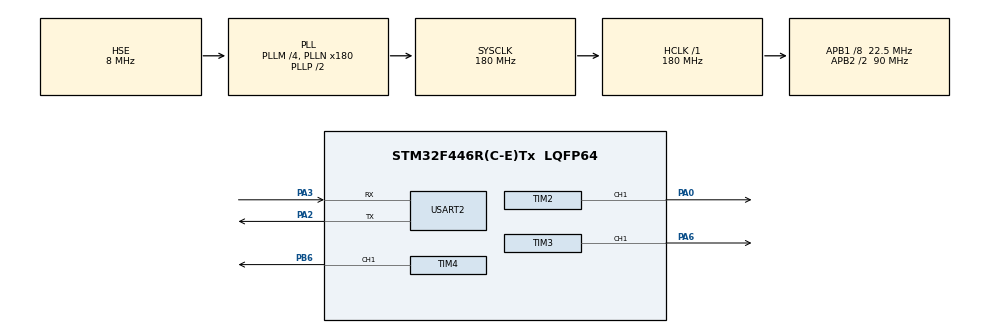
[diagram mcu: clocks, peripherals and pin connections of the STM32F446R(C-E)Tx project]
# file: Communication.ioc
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Mcu.Family=STM32F4
Mcu.Name=STM32F446R(C-E)Tx
Mcu.Package=LQFP64
NVIC.PriorityGroup=NVIC_PRIORITYGROUP_0
NVIC.TIM2_IRQn=true\:0\:0\:false\:false\:true\:true\:true
NVIC.TIM3_IRQn=true\:0\:0\:false\:false\:true\:true\:true
NVIC.TIM4_IRQn=true\:0\:0\:false\:false\:true\:true\:true
NVIC.USART2_IRQn=true\:0\:0\:false\:false\:true\:true\:true
PA0-WKUP.Signal=S_TIM2_CH1_ETR
PA2.Mode=Asynchronous
PA2.Signal=USART2_TX
PA3.Mode=Asynchronous
PA3.Signal=USART2_RX
PA6.Signal=S_TIM3_CH1
PB6.Signal=S_TIM4_CH1
PH0-OSC_IN.Mode=HSE-External-Oscillator
PH0-OSC_IN.Signal=RCC_OSC_IN
PH1-OSC_OUT.Mode=HSE-External-Oscillator
PH1-OSC_OUT.Signal=RCC_OSC_OUT
ProjectManager.HeapSize=0x200
ProjectManager.StackSize=0x400
ProjectManager.TargetToolchain=STM32CubeIDE
RCC.48MHZClocksFreq_Value=84000000
RCC.AHBFreq_Value=180000000
RCC.APB1CLKDivider=RCC_HCLK_DIV8
RCC.APB1Freq_Value=22500000
RCC.APB1TimFreq_Value=45000000
RCC.APB2CLKDivider=RCC_HCLK_DIV2
RCC.APB2Freq_Value=90000000
RCC.APB2TimFreq_Value=180000000
RCC.CortexFreq_Value=180000000
RCC.FLatency-AdvancedSettings=FLASH_LATENCY_5
RCC.HCLKFreq_Value=180000000
RCC.HSE_VALUE=8000000
RCC.HSI_VALUE=16000000
RCC.PLLM=4
RCC.PLLN=180
RCC.PLLSourceVirtual=RCC_PLLSOURCE_HSE
RCC.SYSCLKFreq_VALUE=180000000
RCC.SYSCLKSource=RCC_SYSCLKSOURCE_PLLCLK
RCC.USBFreq_Value=180000000
RCC.VCOOutputFreq_Value=360000000
SH.S_TIM2_CH1_ETR.0=TIM2_CH1,PWM Generation1 CH1
SH.S_TIM3_CH1.0=TIM3_CH1,PWM Generation1 CH1
SH.S_TIM4_CH1.0=TIM4_CH1,PWM Generation1 CH1
TIM2.Channel-PWM\ Generation1\ CH1=TIM_CHANNEL_1
TIM2.Period=1000-1
TIM2.Prescaler=900-1
TIM3.Channel-PWM\ Generation1\ CH1=TIM_CHANNEL_1
TIM3.Period=1000-1
TIM3.Prescaler=900-1
TIM4.Channel-PWM\ Generation1\ CH1=TIM_CHANNEL_1
TIM4.Period=1000-1
TIM4.Prescaler=900-1
USART2.VirtualMode=VM_ASYNC
VP_TIM2_VS_ClockSourceINT.Mode=Internal
VP_TIM3_VS_ClockSourceINT.Mode=Internal
VP_TIM4_VS_ClockSourceINT.Mode=Internal
board=NUCLEO-F446RE

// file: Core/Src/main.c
/* USER CODE BEGIN Header */
/**
  ******************************************************************************
  * @file           : main.c
  * @brief          : Main program body
  ******************************************************************************
  * @attention
  *
  * <h2><center>&copy; Copyright (c) 2020 STMicroelectronics.
  * All rights reserved.</center></h2>
  *
  * This software component is licensed by ST under BSD 3-Clause license,
  * the "License"; You may not use this file except in compliance with the
  * License. You may obtain a copy of the License at:
  *                        opensource.org/licenses/BSD-3-Clause
  *
  ******************************************************************************
  */
/* USER CODE END Header */

#include "main.h"
#include "plotter.h"
#include "image.h"

TIM_HandleTypeDef htim2;
TIM_HandleTypeDef htim3;
TIM_HandleTypeDef htim4;

UART_HandleTypeDef huart2;

void SystemClock_Config(void);
static void MX_GPIO_Init(void);
static void MX_TIM3_Init(void);
static void MX_TIM2_Init(void);
static void MX_USART2_UART_Init(void);
static void MX_TIM4_Init(void);

/* USER CODE BEGIN 0 */

uint8_t Rx_data[1252];	// array for 1252 bytes
uint8_t received = 0;	// flag

void HAL_UART_RxCpltCallback(UART_HandleTypeDef *huart){
	received = 1;
}

/* USER CODE END 0 */

int main(void)
{
  /* USER CODE BEGIN 1 */
  uint8_t FigArray[100][100];	// 2D array that represents the image
  uint8_t size[2];		// size[0]: # of rows, size[1]: # of coloumns
  uint8_t mode = 0;		// mode = 0: linear, mode = 1: spotted
  int numOfBytes;	// number of useful bytes of the image
  /* USER CODE END 1 */

  /* MCU Configuration--------------------------------------------------------*/

  /* Reset of all peripherals, Initializes the Flash interface and the Systick. */
  HAL_Init();

  /* Configure the system clock */
  SystemClock_Config();

  /* Initialize all configured peripherals */
  MX_GPIO_Init();
  MX_TIM3_Init();
  MX_TIM2_Init();
  MX_TIM4_Init();

  MX_USART2_UART_Init();

  /* USER CODE BEGIN 2 */
  HAL_TIM_PWM_Start(&htim2, TIM_CHANNEL_1);	// moves pen
  HAL_TIM_PWM_Start(&htim3, TIM_CHANNEL_1);	// changes coloumn
  HAL_TIM_PWM_Start(&htim4, TIM_CHANNEL_1);	// changes row

  while(1){
	  received = 0;
  HAL_UART_Receive_IT(&huart2, Rx_data, 1252);
  /* USER CODE END 2 */

  /* Infinite loop */
  /* USER CODE BEGIN WHILE */

  while(received == 0);

  computeModeAndSize(Rx_data, size, &mode);

  numOfBytes = computeNumOfBytes(size);

  fillArrayWithZeros(FigArray);

  fillArray(Rx_data, numOfBytes, size, FigArray);

  if(mode == 0){
	  prepareArrayAsLinear(FigArray);
	  printLinear(FigArray);
  }
  else{
	  print(FigArray);
  }
 }
}

void SystemClock_Config(void)
{
  RCC_OscInitTypeDef RCC_OscInitStruct = {0};
  RCC_ClkInitTypeDef RCC_ClkInitStruct = {0};

  /** Configure the main internal regulator output voltage
  */
  __HAL_RCC_PWR_CLK_ENABLE();
  __HAL_PWR_VOLTAGESCALING_CONFIG(PWR_REGULATOR_VOLTAGE_SCALE1);
  /** Initializes the CPU, AHB and APB busses clocks
  */
  RCC_OscInitStruct.OscillatorType = RCC_OSCILLATORTYPE_HSE;
  RCC_OscInitStruct.HSEState = RCC_HSE_ON;
  RCC_OscInitStruct.PLL.PLLState = RCC_PLL_ON;
  RCC_OscInitStruct.PLL.PLLSource = RCC_PLLSOURCE_HSE;
  RCC_OscInitStruct.PLL.PLLM = 4;
  RCC_OscInitStruct.PLL.PLLN = 180;
  RCC_OscInitStruct.PLL.PLLP = RCC_PLLP_DIV2;
  RCC_OscInitStruct.PLL.PLLQ = 2;
  RCC_OscInitStruct.PLL.PLLR = 2;
  if (HAL_RCC_OscConfig(&RCC_OscInitStruct) != HAL_OK)
  {
    Error_Handler();
  }
  /** Activate the Over-Drive mode
  */
  if (HAL_PWREx_EnableOverDrive() != HAL_OK)
  {
    Error_Handler();
  }
  /** Initializes the CPU, AHB and APB busses clocks
  */
  RCC_ClkInitStruct.ClockType = RCC_CLOCKTYPE_HCLK|RCC_CLOCKTYPE_SYSCLK
                              |RCC_CLOCKTYPE_PCLK1|RCC_CLOCKTYPE_PCLK2;
  RCC_ClkInitStruct.SYSCLKSource = RCC_SYSCLKSOURCE_PLLCLK;
  RCC_ClkInitStruct.AHBCLKDivider = RCC_SYSCLK_DIV1;
  RCC_ClkInitStruct.APB1CLKDivider = RCC_HCLK_DIV8;
  RCC_ClkInitStruct.APB2CLKDivider = RCC_HCLK_DIV2;

  if (HAL_RCC_ClockConfig(&RCC_ClkInitStruct, FLASH_LATENCY_5) != HAL_OK)
  {
    Error_Handler();
  }
}

static void MX_TIM2_Init(void)
{

  TIM_ClockConfigTypeDef sClockSourceConfig = {0};
  TIM_MasterConfigTypeDef sMasterConfig = {0};
  TIM_OC_InitTypeDef sConfigOC = {0};

  htim2.Instance = TIM2;
  htim2.Init.Prescaler = 900-1;
  htim2.Init.CounterMode = TIM_COUNTERMODE_UP;
  htim2.Init.Period = 1000-1;
  htim2.Init.ClockDivision = TIM_CLOCKDIVISION_DIV1;
  htim2.Init.AutoReloadPreload = TIM_AUTORELOAD_PRELOAD_DISABLE;
  if (HAL_TIM_Base_Init(&htim2) != HAL_OK)
  {
    Error_Handler();
  }
  sClockSourceConfig.ClockSource = TIM_CLOCKSOURCE_INTERNAL;
  if (HAL_TIM_ConfigClockSource(&htim2, &sClockSourceConfig) != HAL_OK)
  {
    Error_Handler();
  }
  if (HAL_TIM_PWM_Init(&htim2) != HAL_OK)
  {
    Error_Handler();
  }
  sMasterConfig.MasterOutputTrigger = TIM_TRGO_RESET;
  sMasterConfig.MasterSlaveMode = TIM_MASTERSLAVEMODE_DISABLE;
  if (HAL_TIMEx_MasterConfigSynchronization(&htim2, &sMasterConfig) != HAL_OK)
  {
    Error_Handler();
  }
  sConfigOC.OCMode = TIM_OCMODE_PWM1;
  sConfigOC.Pulse = 0;
  sConfigOC.OCPolarity = TIM_OCPOLARITY_HIGH;
  sConfigOC.OCFastMode = TIM_OCFAST_DISABLE;
  if (HAL_TIM_PWM_ConfigChannel(&htim2, &sConfigOC, TIM_CHANNEL_1) != HAL_OK)
  {
    Error_Handler();
  }
  HAL_TIM_MspPostInit(&htim2);

}

static void MX_TIM3_Init(void)
{

  TIM_ClockConfigTypeDef sClockSourceConfig = {0};
  TIM_MasterConfigTypeDef sMasterConfig = {0};
  TIM_OC_InitTypeDef sConfigOC = {0};

  htim3.Instance = TIM3;
  htim3.Init.Prescaler = 900-1;
  htim3.Init.CounterMode = TIM_COUNTERMODE_UP;
  htim3.Init.Period = 1000-1;
  htim3.Init.ClockDivision = TIM_CLOCKDIVISION_DIV1;
  htim3.Init.AutoReloadPreload = TIM_AUTORELOAD_PRELOAD_DISABLE;
  if (HAL_TIM_Base_Init(&htim3) != HAL_OK)
  {
    Error_Handler();
  }
  sClockSourceConfig.ClockSource = TIM_CLOCKSOURCE_INTERNAL;
  if (HAL_TIM_ConfigClockSource(&htim3, &sClockSourceConfig) != HAL_OK)
  {
    Error_Handler();
  }
  if (HAL_TIM_PWM_Init(&htim3) != HAL_OK)
  {
    Error_Handler();
  }
  sMasterConfig.MasterOutputTrigger = TIM_TRGO_RESET;
  sMasterConfig.MasterSlaveMode = TIM_MASTERSLAVEMODE_DISABLE;
  if (HAL_TIMEx_MasterConfigSynchronization(&htim3, &sMasterConfig) != HAL_OK)
  {
    Error_Handler();
  }
  sConfigOC.OCMode = TIM_OCMODE_PWM1;
  sConfigOC.Pulse = 0;
  sConfigOC.OCPolarity = TIM_OCPOLARITY_HIGH;
  sConfigOC.OCFastMode = TIM_OCFAST_DISABLE;
  if (HAL_TIM_PWM_ConfigChannel(&htim3, &sConfigOC, TIM_CHANNEL_1) != HAL_OK)
  {
    Error_Handler();
  }
  HAL_TIM_MspPostInit(&htim3);

}

static void MX_TIM4_Init(void)
{

  TIM_ClockConfigTypeDef sClockSourceConfig = {0};
  TIM_MasterConfigTypeDef sMasterConfig = {0};
  TIM_OC_InitTypeDef sConfigOC = {0};

  htim4.Instance = TIM4;
  htim4.Init.Prescaler = 900-1;
  htim4.Init.CounterMode = TIM_COUNTERMODE_UP;
  htim4.Init.Period = 1000-1;
  htim4.Init.ClockDivision = TIM_CLOCKDIVISION_DIV1;
  htim4.Init.AutoReloadPreload = TIM_AUTORELOAD_PRELOAD_DISABLE;
  if (HAL_TIM_Base_Init(&htim4) != HAL_OK)
  {
    Error_Handler();
  }
  sClockSourceConfig.ClockSource = TIM_CLOCKSOURCE_INTERNAL;
  if (HAL_TIM_ConfigClockSource(&htim4, &sClockSourceConfig) != HAL_OK)
  {
    Error_Handler();
  }
  if (HAL_TIM_PWM_Init(&htim4) != HAL_OK)
  {
    Error_Handler();
  }
  sMasterConfig.MasterOutputTrigger = TIM_TRGO_RESET;
  sMasterConfig.MasterSlaveMode = TIM_MASTERSLAVEMODE_DISABLE;
  if (HAL_TIMEx_MasterConfigSynchronization(&htim4, &sMasterConfig) != HAL_OK)
  {
    Error_Handler();
  }
  sConfigOC.OCMode = TIM_OCMODE_PWM1;
  sConfigOC.Pulse = 0;
  sConfigOC.OCPolarity = TIM_OCPOLARITY_HIGH;
  sConfigOC.OCFastMode = TIM_OCFAST_DISABLE;
  if (HAL_TIM_PWM_ConfigChannel(&htim4, &sConfigOC, TIM_CHANNEL_1) != HAL_OK)
  {
    Error_Handler();
  }
  HAL_TIM_MspPostInit(&htim4);

}

static void MX_USART2_UART_Init(void)
{

  huart2.Instance = USART2;
  huart2.Init.BaudRate = 115200;
  huart2.Init.WordLength = UART_WORDLENGTH_8B;
  huart2.Init.StopBits = UART_STOPBITS_1;
  huart2.Init.Parity = UART_PARITY_NONE;
  huart2.Init.Mode = UART_MODE_TX_RX;
  huart2.Init.HwFlowCtl = UART_HWCONTROL_NONE;
  huart2.Init.OverSampling = UART_OVERSAMPLING_16;
  if (HAL_UART_Init(&huart2) != HAL_OK)
  {
    Error_Handler();
  }

}

static void MX_GPIO_Init(void)
{

  /* GPIO Ports Clock Enable */
  __HAL_RCC_GPIOH_CLK_ENABLE();
  __HAL_RCC_GPIOA_CLK_ENABLE();
  __HAL_RCC_GPIOB_CLK_ENABLE();

}

void Error_Handler(void)
{
}

/************************ (C) COPYRIGHT STMicroelectronics *****END OF FILE****/
